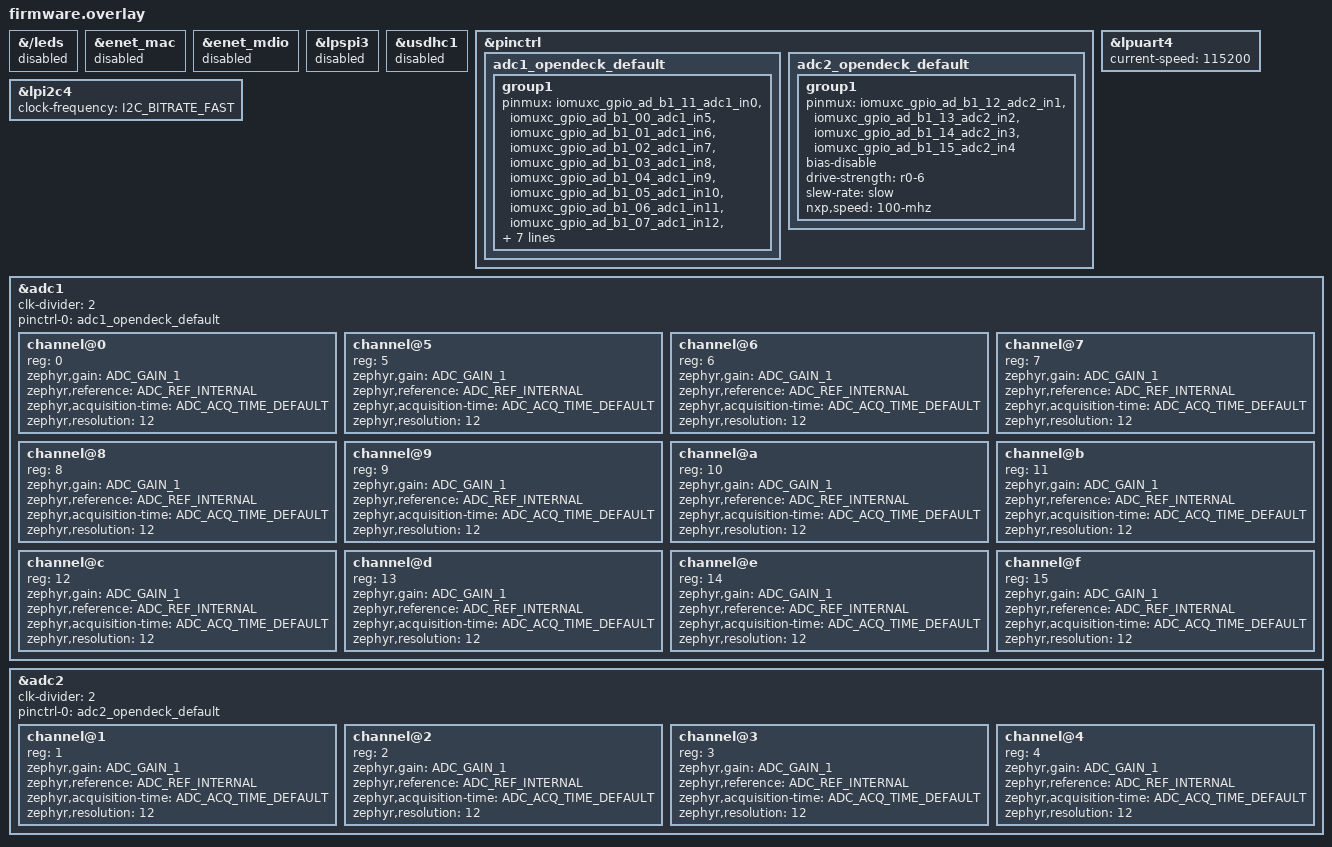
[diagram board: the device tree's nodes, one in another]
#include <zephyr/dt-bindings/adc/adc.h>

&{/leds} {
    status = "disabled";
};

&enet_mac {
    status = "disabled";
};

&enet_mdio {
    status = "disabled";
};

&lpspi3 {
    status = "disabled";
};

&usdhc1 {
    status = "disabled";
};

&pinctrl {
    adc1_opendeck_default: adc1_opendeck_default {
        group1 {
            pinmux = <&iomuxc_gpio_ad_b1_11_adc1_in0>,
                     <&iomuxc_gpio_ad_b1_00_adc1_in5>,
                     <&iomuxc_gpio_ad_b1_01_adc1_in6>,
                     <&iomuxc_gpio_ad_b1_02_adc1_in7>,
                     <&iomuxc_gpio_ad_b1_03_adc1_in8>,
                     <&iomuxc_gpio_ad_b1_04_adc1_in9>,
                     <&iomuxc_gpio_ad_b1_05_adc1_in10>,
                     <&iomuxc_gpio_ad_b1_06_adc1_in11>,
                     <&iomuxc_gpio_ad_b1_07_adc1_in12>,
                     <&iomuxc_gpio_ad_b1_08_adc1_in13>,
                     <&iomuxc_gpio_ad_b1_09_adc1_in14>,
                     <&iomuxc_gpio_ad_b1_10_adc1_in15>;
            bias-disable;
            drive-strength = "r0-6";
            slew-rate = "slow";
            nxp,speed = "100-mhz";
        };
    };

    adc2_opendeck_default: adc2_opendeck_default {
        group1 {
            pinmux = <&iomuxc_gpio_ad_b1_12_adc2_in1>,
                     <&iomuxc_gpio_ad_b1_13_adc2_in2>,
                     <&iomuxc_gpio_ad_b1_14_adc2_in3>,
                     <&iomuxc_gpio_ad_b1_15_adc2_in4>;
            bias-disable;
            drive-strength = "r0-6";
            slew-rate = "slow";
            nxp,speed = "100-mhz";
        };
    };
};

&lpuart4 {
    /* Teensy pins 8 (TX4) / 7 (RX4) */
    current-speed = <115200>;
    status = "okay";
};

&lpi2c4 {
    /* Teensy pins 24 (SCL2) / 25 (SDA2) */
    clock-frequency = <I2C_BITRATE_FAST>;
    status = "okay";
};

&adc1 {
    status = "okay";
    clk-divider = <2>;
    pinctrl-0 = <&adc1_opendeck_default>;
    pinctrl-names = "default";
    #address-cells = <1>;
    #size-cells = <0>;

    channel@0 {
        reg = <0>;
        zephyr,gain = "ADC_GAIN_1";
        zephyr,reference = "ADC_REF_INTERNAL";
        zephyr,acquisition-time = <ADC_ACQ_TIME_DEFAULT>;
        zephyr,resolution = <12>;
    };

    channel@5 {
        reg = <5>;
        zephyr,gain = "ADC_GAIN_1";
        zephyr,reference = "ADC_REF_INTERNAL";
        zephyr,acquisition-time = <ADC_ACQ_TIME_DEFAULT>;
        zephyr,resolution = <12>;
    };

    channel@6 {
        reg = <6>;
        zephyr,gain = "ADC_GAIN_1";
        zephyr,reference = "ADC_REF_INTERNAL";
        zephyr,acquisition-time = <ADC_ACQ_TIME_DEFAULT>;
        zephyr,resolution = <12>;
    };

    channel@7 {
        reg = <7>;
        zephyr,gain = "ADC_GAIN_1";
        zephyr,reference = "ADC_REF_INTERNAL";
        zephyr,acquisition-time = <ADC_ACQ_TIME_DEFAULT>;
        zephyr,resolution = <12>;
    };

    channel@8 {
        reg = <8>;
        zephyr,gain = "ADC_GAIN_1";
        zephyr,reference = "ADC_REF_INTERNAL";
        zephyr,acquisition-time = <ADC_ACQ_TIME_DEFAULT>;
        zephyr,resolution = <12>;
    };

    channel@9 {
        reg = <9>;
        zephyr,gain = "ADC_GAIN_1";
        zephyr,reference = "ADC_REF_INTERNAL";
        zephyr,acquisition-time = <ADC_ACQ_TIME_DEFAULT>;
        zephyr,resolution = <12>;
    };

    channel@a {
        reg = <10>;
        zephyr,gain = "ADC_GAIN_1";
        zephyr,reference = "ADC_REF_INTERNAL";
        zephyr,acquisition-time = <ADC_ACQ_TIME_DEFAULT>;
        zephyr,resolution = <12>;
    };

    channel@b {
        reg = <11>;
        zephyr,gain = "ADC_GAIN_1";
        zephyr,reference = "ADC_REF_INTERNAL";
        zephyr,acquisition-time = <ADC_ACQ_TIME_DEFAULT>;
        zephyr,resolution = <12>;
    };

    channel@c {
        reg = <12>;
        zephyr,gain = "ADC_GAIN_1";
        zephyr,reference = "ADC_REF_INTERNAL";
        zephyr,acquisition-time = <ADC_ACQ_TIME_DEFAULT>;
        zephyr,resolution = <12>;
    };

    channel@d {
        reg = <13>;
        zephyr,gain = "ADC_GAIN_1";
        zephyr,reference = "ADC_REF_INTERNAL";
        zephyr,acquisition-time = <ADC_ACQ_TIME_DEFAULT>;
        zephyr,resolution = <12>;
    };

    channel@e {
        reg = <14>;
        zephyr,gain = "ADC_GAIN_1";
        zephyr,reference = "ADC_REF_INTERNAL";
        zephyr,acquisition-time = <ADC_ACQ_TIME_DEFAULT>;
        zephyr,resolution = <12>;
    };

    channel@f {
        reg = <15>;
        zephyr,gain = "ADC_GAIN_1";
        zephyr,reference = "ADC_REF_INTERNAL";
        zephyr,acquisition-time = <ADC_ACQ_TIME_DEFAULT>;
        zephyr,resolution = <12>;
    };
};

&adc2 {
    status = "okay";
    clk-divider = <2>;
    pinctrl-0 = <&adc2_opendeck_default>;
    pinctrl-names = "default";
    #address-cells = <1>;
    #size-cells = <0>;

    channel@1 {
        reg = <1>;
        zephyr,gain = "ADC_GAIN_1";
        zephyr,reference = "ADC_REF_INTERNAL";
        zephyr,acquisition-time = <ADC_ACQ_TIME_DEFAULT>;
        zephyr,resolution = <12>;
    };

    channel@2 {
        reg = <2>;
        zephyr,gain = "ADC_GAIN_1";
        zephyr,reference = "ADC_REF_INTERNAL";
        zephyr,acquisition-time = <ADC_ACQ_TIME_DEFAULT>;
        zephyr,resolution = <12>;
    };

    channel@3 {
        reg = <3>;
        zephyr,gain = "ADC_GAIN_1";
        zephyr,reference = "ADC_REF_INTERNAL";
        zephyr,acquisition-time = <ADC_ACQ_TIME_DEFAULT>;
        zephyr,resolution = <12>;
    };

    channel@4 {
        reg = <4>;
        zephyr,gain = "ADC_GAIN_1";
        zephyr,reference = "ADC_REF_INTERNAL";
        zephyr,acquisition-time = <ADC_ACQ_TIME_DEFAULT>;
        zephyr,resolution = <12>;
    };
};
